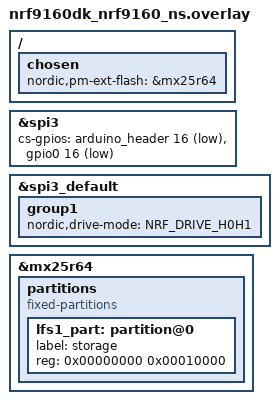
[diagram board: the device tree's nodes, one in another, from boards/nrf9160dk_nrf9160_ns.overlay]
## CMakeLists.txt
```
#
# Copyright (c) 2022 Nordic Semiconductor
#
# SPDX-License-Identifier: LicenseRef-Nordic-5-Clause
#

cmake_minimum_required(VERSION 3.20.0)

find_package(Zephyr REQUIRED HINTS $ENV{ZEPHYR_BASE})
project(modem_trace_flash)

if(CONFIG_NRF_MODEM_LIB_TRACE)

# Only add 'custom' backend to compilation when selected.
zephyr_library_sources_ifdef(
  CONFIG_NRF_MODEM_LIB_TRACE_BACKEND_FLASH
  src/trace_flash.c
)

endif()

# NORDIC SDK APP START
target_sources(app PRIVATE src/main.c)

# NORDIC SDK APP END
```

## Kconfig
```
#
# Copyright (c) 2022 Nordic Semiconductor
#
# SPDX-License-Identifier: LicenseRef-Nordic-5-Clause
#

menu "Modem trace flash backend sample"

endmenu

module = MODEM_TRACE_FLASH_SAMPLE
module-str = Modem trace flash backend
source "${ZEPHYR_BASE}/subsys/logging/Kconfig.template.log_config"

rsource "Kconfig.trace_flash"

menu "Zephyr Kernel"
source "Kconfig.zephyr"
endmenu
```

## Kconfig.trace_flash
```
#
# Copyright (c) 2022 Nordic Semiconductor
#
# SPDX-License-Identifier: LicenseRef-Nordic-5-Clause
#

module = MODEM_TRACE_FLASH_BACKEND
module-str = Modem trace flash backend
source "${ZEPHYR_BASE}/subsys/logging/Kconfig.template.log_config"

if NRF_MODEM_LIB_TRACE

# Adds NRF_MODEM_LIB_TRACE_BACKEND_CUSTOM to the trace backend choice.
choice NRF_MODEM_LIB_TRACE_BACKEND

config NRF_MODEM_LIB_TRACE_BACKEND_FLASH
	bool "Stream modem traces to flash"
	help
	  Stream modem trace data to flash.

endchoice # NRF_MODEM_LIB_TRACE_BACKEND

endif # NRF_MODEM_LIB_TRACE_ENABLED
```

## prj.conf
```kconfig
#
# Copyright (c) 2022 Nordic Semiconductor ASA
#
# SPDX-License-Identifier: LicenseRef-Nordic-5-Clause
#

# Allow the application to reboot
CONFIG_REBOOT=y

# Logging
CONFIG_LOG=y
CONFIG_NRF_MODEM_LIB_LOG_LEVEL_INF=y
CONFIG_MODEM_TRACE_FLASH_SAMPLE_LOG_LEVEL_DBG=y
CONFIG_MODEM_TRACE_BACKEND_LOG_LEVEL_DBG=y

#CONFIG_NRF_MODEM_LIB_TRACE_BITRATE_LOG=y
#CONFIG_NRF_MODEM_LIB_TRACE_BACKEND_BITRATE_LOG=y

# Modem library
CONFIG_NRF_MODEM_LIB=y
# Manual init of modem lib needed to let Zephyr init flash device before trace_flash backend
CONFIG_NRF_MODEM_LIB_SYS_INIT=n

# LTE link control
CONFIG_LTE_LINK_CONTROL=y
CONFIG_LTE_AUTO_INIT_AND_CONNECT=n

# Modem trace
CONFIG_NRF_MODEM_LIB_TRACE=y
CONFIG_NRF_MODEM_LIB_TRACE_BACKEND_FLASH=y

# Flash config
CONFIG_FCB=y
CONFIG_FLASH=y
CONFIG_FLASH_MAP=y

#increase trace write speed
CONFIG_FCB_ALLOW_FIXED_ENDMARKER=y
CONFIG_NRF_MODEM_TRACE_FLASH_NOSPACE_SIGNAL=y

# Heap and stacks
CONFIG_HEAP_MEM_POOL_SIZE=2048
CONFIG_MAIN_STACK_SIZE=4096
CONFIG_SYSTEM_WORKQUEUE_STACK_SIZE=4096
CONFIG_NRF_MODEM_LIB_TRACE_STACK_SIZE=4096

# GPIO
CONFIG_GPIO=y

# Library for buttons and LEDs
CONFIG_DK_LIBRARY=y

# UART
CONFIG_SERIAL=y
```

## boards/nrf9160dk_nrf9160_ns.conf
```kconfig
#
# Copyright (c) 2022 Nordic Semiconductor ASA
#
# SPDX-License-Identifier: Apache-2.0
#

# Need this when storage is on flash
CONFIG_MPU_ALLOW_FLASH_WRITE=y

# Need this when storage is on MX25R64
#CONFIG_NORDIC_QSPI_NOR=y
#CONFIG_NORDIC_QSPI_NOR_FLASH_LAYOUT_PAGE_SIZE=4096

CONFIG_SPI=y
CONFIG_SPI_NOR=y
CONFIG_SPI_NOR_FLASH_LAYOUT_PAGE_SIZE=4096

# Configure partition manager that littlefs should be on external flash
CONFIG_PM_PARTITION_REGION_LITTLEFS_EXTERNAL=y
CONFIG_PM_PARTITION_SIZE_LITTLEFS=0x800000

CONFIG_PM_OVERRIDE_EXTERNAL_DRIVER_CHECK=y
# CONFIG_FS_LITTLEFS_BLK_DEV ?
```

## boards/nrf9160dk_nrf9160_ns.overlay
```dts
/*
 * Copyright (c) 2022 Nordic Semiconductor ASA
 *
 * SPDX-License-Identifier: LicenseRef-Nordic-5-Clause
 */

 /delete-node/ &storage_partition;

// / {
// 	fstab {
// 		compatible = "zephyr,fstab";
// 		lfs1: lfs1 {
// 			compatible = "zephyr,fstab,littlefs";
// 			mount-point = "/lfs1";
// 			partition = <&lfs1_part>;
// 			automount;
// 			read-size = <16>;
// 			prog-size = <16>;
// 			cache-size = <64>;
// 			lookahead-size = <32>;
// 			block-cycles = <512>;
// 		};
// 	};
// };

/ {
	chosen {
		nordic,pm-ext-flash = &mx25r64;
	};
};

/* TODO: REMOVE THIS - ONLY FOR PIN TRACING WITH CUT SB23 */
&spi3 {
	cs-gpios = <&arduino_header 16 GPIO_ACTIVE_LOW>, /* D10 */
		   <&gpio0 16 GPIO_ACTIVE_LOW>;
};

/* Increase SPI3 drive strenght */
&spi3_default {
	group1 {
		nordic,drive-mode = <NRF_DRIVE_H0H1>;
	};
};

&mx25r64 {
	partitions {
		compatible = "fixed-partitions";
		#address-cells = <1>;
		#size-cells = <1>;

		lfs1_part: partition@0 {
			label = "storage";
			reg = <0x00000000 0x00010000>;
		};
	};
};
```

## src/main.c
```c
/*
 * Copyright (c) 2022 Nordic Semiconductor ASA
 *
 * SPDX-License-Identifier: LicenseRef-Nordic-5-Clause
 */

#include <zephyr/kernel.h>
#include <zephyr/logging/log.h>
#include <zephyr/device.h>
#include <zephyr/drivers/uart.h>
#include <modem/lte_lc.h>
#include <modem/nrf_modem_lib.h>
#include <modem/nrf_modem_lib_trace.h>
#include <nrf_modem.h>
#include <nrf_modem_at.h>
#include <dk_buttons_and_leds.h>

#include <zephyr/sys/reboot.h>

LOG_MODULE_REGISTER(modem_trace_flash_sample, CONFIG_MODEM_TRACE_FLASH_SAMPLE_LOG_LEVEL);

#define UART1_DT_NODE DT_NODELABEL(uart1)

#define READ_BUF_SIZE CONFIG_NRF_MODEM_LIB_TRACE_BACKEND_FLASH_BUF_SIZE

static const struct device *const uart_dev = DEVICE_DT_GET(UART1_DT_NODE);

LTE_LC_ON_CFUN(cfun_hook, on_cfun, NULL);

/* Callback for when modem functional mode is changed */
static void on_cfun(enum lte_lc_func_mode mode, void *context)
{
	LOG_INF("LTE mode changed to %d\n", mode);
}

static void print_uart1(char *buf, int len)
{
	if (!device_is_ready(uart_dev)) {
		LOG_ERR("uart1 device not found/ready!");
		return;
	}
	for (int i = 0; i < len; i++) {
		uart_poll_out(uart_dev, buf[i]);
	}
}

static void print_traces(void)
{
	uint8_t read_buf[READ_BUF_SIZE];
	int ret;
	size_t read_offset = 0;

	ret = nrf_modem_lib_trace_data_size();
	printk("Reading out %d bytes of trace data\n", ret);

	/* Read out the trace data from flash */
	while (ret > 0) {
		ret = nrf_modem_lib_trace_read(read_buf, READ_BUF_SIZE);
		if (ret < 0) {
			if (ret == -ENODATA) {
				break;
			}
			LOG_ERR("Error reading modem traces: %d", ret);
			break;
		}
		if (ret == 0) {
			LOG_DBG("No more traces to read from flash");
			break;
		}

		read_offset += ret;
		print_uart1(read_buf, ret);
	}
	LOG_INF("Total trace bytes read from flash: %d", read_offset);
}

static void button_handler(uint32_t button_states, uint32_t has_changed)
{
	if (has_changed & button_states & DK_BTN1_MSK) {
		printk("Button 1 pressed - dumping traces to uart1\n");
		print_traces();
	}

	if (has_changed & button_states & DK_BTN2_MSK) {
		printk("Button 2 pressed - restarting application\n");
		sys_reboot(SYS_REBOOT_WARM);
	}
}

void main(void)
{
	int err;

	LOG_INF("Modem trace backend sample started\n");

	err = dk_buttons_init(button_handler);
	if (err) {
		LOG_ERR("Failed to initialize DK buttons library, error: %d\n", err);
	}

	if (!device_is_ready(uart_dev)) {
		LOG_ERR("uart1 device not found/ready!");
	}

	nrf_modem_lib_init(NORMAL_MODE);

	err = nrf_modem_lib_trace_level_set(NRF_MODEM_LIB_TRACE_LEVEL_FULL);
	if (err) {
		LOG_ERR("Failed to enable modem traces");
	}

	LOG_INF("Connecting to network\n");

	err = lte_lc_func_mode_set(LTE_LC_FUNC_MODE_NORMAL);
	if (err) {
		LOG_ERR("Failed to change LTE mode, err %d\n", err);
		return;
	}

	/* Leave the modem on for 10 seconds */
	k_sleep(K_SECONDS(10));

	err = lte_lc_func_mode_set(LTE_LC_FUNC_MODE_POWER_OFF);
	if (err) {
		LOG_ERR("Failed to change LTE mode, err %d\n", err);
		return;
	}

	/* Give the modem some time to turn off and receive traces */
	k_sleep(K_SECONDS(5));

	err = nrf_modem_lib_trace_level_set(NRF_MODEM_LIB_TRACE_LEVEL_OFF);
	if (err) {
		LOG_ERR("Failed to turn off modem traces\n");
	} else {
		LOG_INF("Turned off modem traces\n");
	}

	/* Changing the trace level to off will produce some traces, so sleep long enough to
	 * receive those as well.
	 */
	k_sleep(K_SECONDS(1));

	LOG_INF("Press button 1 to print traces to UART");
	LOG_INF("Press button 2 to restart application (warm boot)");
}
```

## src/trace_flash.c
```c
/*
 * Copyright (c) 2022 Nordic Semiconductor ASA
 *
 * SPDX-License-Identifier: LicenseRef-Nordic-5-Clause
 */

#include <zephyr/zephyr.h>
#include <stdio.h>
#include <stddef.h>
#include <zephyr/device.h>
#include <zephyr/fs/fs.h>
#include <zephyr/fs/littlefs.h>
#include <zephyr/logging/log.h>
#include <zephyr/storage/flash_map.h>
#include <modem/trace_backend.h>

LOG_MODULE_REGISTER(modem_trace_flash_backend, CONFIG_MODEM_TRACE_FLASH_BACKEND_LOG_LEVEL);

FS_LITTLEFS_DECLARE_DEFAULT_CONFIG(storage);
static struct fs_mount_t littlefs_mnt = {
	.type = FS_LITTLEFS,
	.fs_data = &storage,
	.storage_dev = (void *)FLASH_AREA_ID(storage),
	.mnt_point = "/lfs",
};
static char filename[20];
static struct fs_file_t file;
static uint32_t tot_bytes_rcvd = 0;
static int64_t tot_write_time;

int littlefs_init(void);
int littlefs_deinit(void);
int littlefs_write(const void *data, size_t len);
void read_file(void);

static trace_backend_processed_cb trace_processed_callback;
int trace_backend_init(trace_backend_processed_cb trace_processed_cb)
{
	if (trace_processed_cb == NULL) {
		return -EFAULT;
	}

	trace_processed_callback = trace_processed_cb;
	tot_write_time = 0;

	return littlefs_init();
}

int trace_backend_deinit(void)
{
	return littlefs_deinit();
}

int trace_backend_write(const void *data, size_t len)
{
	return littlefs_write(data, len);
}


static int littlefs_erase(unsigned int id)
{
	const struct flash_area *fa;
	
	int err = flash_area_open(id, &fa);
	if (err) {
		LOG_ERR("Error opening flash area %u: %d\n", id, err);
		return err;
	}

	err = flash_area_erase(fa, 0, fa->fa_size);
	if (err) {
		LOG_ERR("Error erasing flash area %d", err);
		return err;
	}
	
	flash_area_close(fa);
	return 0;
}

int littlefs_init(void)
{
	int err;
	struct fs_statvfs sbuf;

	LOG_INF("Flash trace backend init");

	// TODO Kconfig for erasing flash or not
	// err = littlefs_erase((uintptr_t) littlefs_mnt.storage_dev);
	// if (err) {
	//     return err;
	// }

	err = fs_mount(&littlefs_mnt);
	if (err) {
		LOG_ERR("fs_mount error: %d", err);
		return err;
	}
	LOG_INF("Mounted %s\n", littlefs_mnt.mnt_point);
	
	err = fs_statvfs(littlefs_mnt.mnt_point, &sbuf);
	if (err < 0) {
		LOG_ERR("statvfs: %d", err);
		fs_unmount(&littlefs_mnt);
		return err;
	}

	LOG_INF("%s: bsize = %lu ; frsize = %lu ;"
		   " blocks = %lu ; bfree = %lu",
		   littlefs_mnt.mnt_point,
		   sbuf.f_bsize, sbuf.f_frsize,
		   sbuf.f_blocks, sbuf.f_bfree);

	struct fs_dir_t dirp;

	fs_dir_t_init(&dirp);
	fs_file_t_init(&file);

	// err = lsdir(littlefs_mnt.mnt_point);
	// if (err < 0) {
	// 	LOG_ERR("lsdir %s: %d", littlefs_mnt.mnt_point, err);
	// 	fs_unmount(&littlefs_mnt);
	// 	return err;
	// }

	snprintf(filename, sizeof(filename), "%s/modem.trace", littlefs_mnt.mnt_point);
	LOG_INF("Storing modem traces to: %s", filename);

	// LOG_INF("Reading %s from previous run", filename);
	// read_file();

	// LOG_INF("Deleting %s", filename);
	// fs_unlink(filename);

	LOG_INF("Creating %s", filename);
	int ret = fs_open(&file, filename, FS_O_CREATE | FS_O_WRITE | FS_O_APPEND);
	if (ret) {
		LOG_ERR("Error opening file %s: %d", filename, ret);
		return ret;
	}

	return 0;
}

void read_file(void)
{
	const uint16_t BUF_SIZE = 255;
	uint8_t data[BUF_SIZE];
	int file_num_bytes = 0;
	int ret = fs_open(&file, filename, FS_O_READ);
	if (ret) {
		LOG_ERR("Error opening file %s: %d", filename, ret);
		return;
	}

	while(true) {
		ret = fs_read(&file, data, BUF_SIZE);
		if (ret < 0) {
			LOG_ERR("fs_read error: %d", ret);
			break;
		} else if (ret == 0) {
			break;
		}
		file_num_bytes += ret;
	}

	LOG_INF("Modem trace bytes read from flash: %d", file_num_bytes);

	if (tot_bytes_rcvd > 0) {
		LOG_INF("Modem trace bytes received from modem: %d", tot_bytes_rcvd);
		LOG_INF("Written %d bytes in %lld ms", file_num_bytes, tot_write_time);
		LOG_INF("Throughput = %lld kb/s ", (file_num_bytes * 8 / tot_write_time));
	}

	ret = fs_close(&file);
	if (ret) {
		LOG_ERR("Error closing %s: %d", filename, ret);
	}
}

int littlefs_deinit(void)
{
	int err = fs_close(&file);
	if (err) {
		LOG_ERR("Error closing %s: %d", filename, err);
	}

	read_file();

	err = fs_unmount(&littlefs_mnt);
	if (err) {
		LOG_ERR("Error unmounting %s: %d", littlefs_mnt.mnt_point, err);
		return err;
	}

	LOG_INF("Unmounted %s", littlefs_mnt.mnt_point);
	return 0;
}

int littlefs_write(const void *data, size_t len)
{
	ssize_t ret;
	tot_bytes_rcvd += len;

	int64_t uptime_ref = k_uptime_get();
	int64_t write_time;

	ret = fs_write(&file, data, len);
	if (ret < 0) {
		LOG_ERR("fs_write error: %d", (int) ret);
	} else if (ret < len) {
		LOG_ERR("fs_write errno: %d (full flash?)", errno);
		ret = errno;
	}

	write_time = k_uptime_delta(&uptime_ref);
	tot_write_time += write_time;

	int err = trace_processed_callback(len);

	if (err) {
		LOG_ERR("trace_processed_callback error: %d", err);
		return err;
	}

	return ret;
}
```
